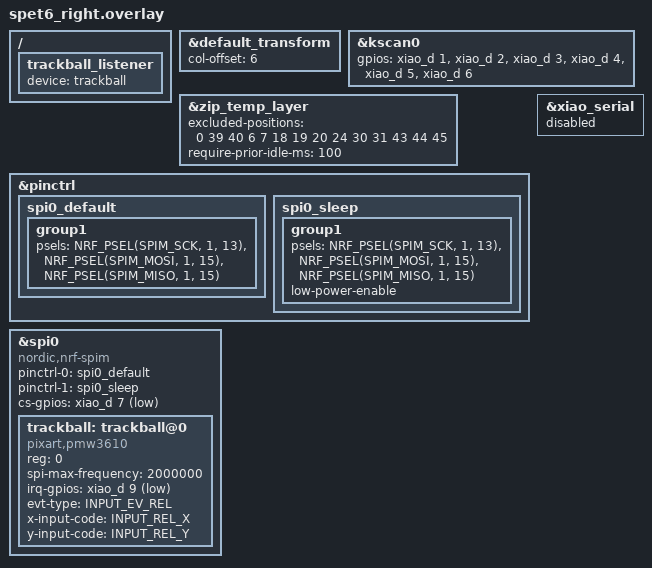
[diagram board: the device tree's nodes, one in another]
/*
 * Copyright (c) 2020 Pete Johanson
 *
 * SPDX-License-Identifier: MIT
 */

#include "spet6.dtsi"
#include <input/processors.dtsi>

&default_transform {
    col-offset = <6>;
};

&kscan0 {
    gpios
        = <&xiao_d 1 (GPIO_ACTIVE_HIGH)>
        , <&xiao_d 2 (GPIO_ACTIVE_HIGH)>
        , <&xiao_d 3 (GPIO_ACTIVE_HIGH)>
        , <&xiao_d 4 (GPIO_ACTIVE_HIGH)>
        , <&xiao_d 5 (GPIO_ACTIVE_HIGH)>
        , <&xiao_d 6 (GPIO_ACTIVE_HIGH)>
        ;
};


/ {
    trackball_listener {
        status = "okay";
        device = <&trackball>;
    };
};

// ここに指定したキーではAMLから抜けなくなる
&zip_temp_layer {
    excluded-positions = <
        0  // exit mouse_layer
        39 // exit mouse_layer
        40 // exit mouse_layer
        6  // F(Prev)
        7  // W(Next)
        18 // K(左クリック)
        19 // T(右クリック)
        20 // N(中クリック)  
        24 // Shift
        30 // PreciseLayer
        31 // PreciseLayer
        43 // Left Click
        44 // Mid Click
        45 // Right Click
    >;
    require-prior-idle-ms = <100>;
};

&pinctrl {
    spi0_default: spi0_default {
        group1 {
            psels = <NRF_PSEL(SPIM_SCK, 1, 13)>, // xiao D8, see posix_seeed_xiao.overlay in zmk source
            <NRF_PSEL(SPIM_MOSI, 1, 15)>, // xiao D10
            <NRF_PSEL(SPIM_MISO, 1, 15)>; // The same to MOSI (Half-duplex mode)
        };
    };

    spi0_sleep: spi0_sleep {
        group1 {
            psels = <NRF_PSEL(SPIM_SCK, 1, 13)>,
                    <NRF_PSEL(SPIM_MOSI, 1, 15)>,
                    <NRF_PSEL(SPIM_MISO, 1, 15)>;
            low-power-enable;
        };
    };
};

&xiao_serial { status = "disabled"; };

&spi0 {
    status = "okay";
    compatible = "nordic,nrf-spim";
    pinctrl-0 = <&spi0_default>;
    pinctrl-1 = <&spi0_sleep>;
    pinctrl-names = "default", "sleep";
    cs-gpios = <&xiao_d 7 GPIO_ACTIVE_LOW>;

    trackball: trackball@0 {
        status = "okay";
        compatible = "pixart,pmw3610";
        reg = <0>;
        // 2MHz suggested in datasheet
        spi-max-frequency = <2000000>;
        irq-gpios = <&xiao_d 9 (GPIO_ACTIVE_LOW | GPIO_PULL_UP)>;
        evt-type = <INPUT_EV_REL>;
        x-input-code = <INPUT_REL_X>;
        y-input-code = <INPUT_REL_Y>;
    };
};
